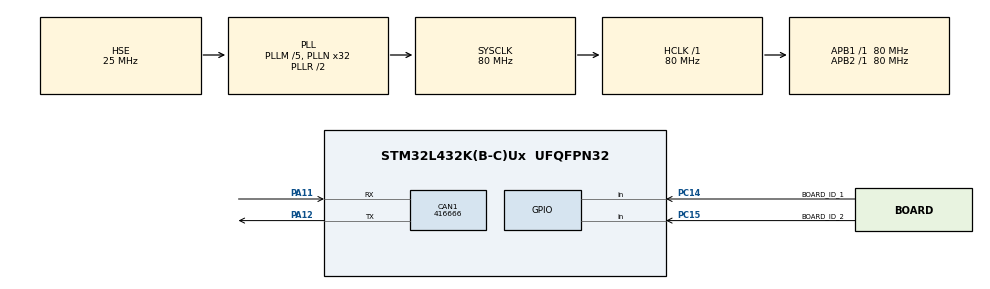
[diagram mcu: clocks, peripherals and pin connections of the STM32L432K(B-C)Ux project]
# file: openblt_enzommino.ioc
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CAN1.BS1=CAN_BS1_10TQ
CAN1.BS2=CAN_BS2_1TQ
CAN1.CalculateBaudRate=416666
CAN1.CalculateTimeBit=2400
CAN1.CalculateTimeQuantum=200.0
Mcu.Family=STM32L4
Mcu.Name=STM32L432K(B-C)Ux
Mcu.Package=UFQFPN32
NVIC.PriorityGroup=NVIC_PRIORITYGROUP_4
PA0.Mode=HSE-External-Clock-Source-for-LittleOrca
PA0.Signal=RCC_CK_IN
PA11.Mode=CAN_Activate
PA11.Signal=CAN1_RX
PA12.Mode=CAN_Activate
PA12.Signal=CAN1_TX
PA13\ (JTMS-SWDIO).Mode=Serial_Wire
PA13\ (JTMS-SWDIO).Signal=SYS_JTMS-SWDIO
PA14\ (JTCK-SWCLK).Mode=Serial_Wire
PA14\ (JTCK-SWCLK).Signal=SYS_JTCK-SWCLK
PC14-OSC32_IN\ (PC14).GPIO_Label=BOARD_ID_1
PC14-OSC32_IN\ (PC14).GPIO_PuPd=GPIO_PULLUP
PC14-OSC32_IN\ (PC14).Signal=GPIO_Input
PC15-OSC32_OUT\ (PC15).GPIO_Label=BOARD_ID_2
PC15-OSC32_OUT\ (PC15).GPIO_PuPd=GPIO_PULLUP
PC15-OSC32_OUT\ (PC15).Signal=GPIO_Input
ProjectManager.HeapSize=0x200
ProjectManager.StackSize=0x400
ProjectManager.TargetToolchain=Makefile
RCC.ADCFreq_Value=20000000
RCC.AHBFreq_Value=80000000
RCC.APB1Freq_Value=80000000
RCC.APB1TimFreq_Value=80000000
RCC.APB2Freq_Value=80000000
RCC.APB2TimFreq_Value=80000000
RCC.CortexFreq_Value=80000000
RCC.HCLKFreq_Value=80000000
RCC.HSE_VALUE=25000000
RCC.HSI48_VALUE=48000000
RCC.HSI_VALUE=16000000
RCC.LSE_VALUE=32768
RCC.MSI_VALUE=4000000
RCC.PLLM=5
RCC.PLLN=32
RCC.PLLSourceVirtual=RCC_PLLSOURCE_HSE
RCC.SYSCLKFreq_VALUE=80000000
RCC.SYSCLKSource=RCC_SYSCLKSOURCE_PLLCLK
RCC.USBFreq_Value=20000000
RCC.VCOOutputFreq_Value=160000000
board=custom

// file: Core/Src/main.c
/* USER CODE BEGIN Header */
/**
 ******************************************************************************
 * @file           : main.c
 * @brief          : Main program body
 ******************************************************************************
 * @attention
 *
 * Copyright (c) 2022 STMicroelectronics.
 * All rights reserved.
 *
 * This software is licensed under terms that can be found in the LICENSE file
 * in the root directory of this software component.
 * If no LICENSE file comes with this software, it is provided AS-IS.
 *
 ******************************************************************************
 */
/* USER CODE END Header */
#include "main.h"

/* USER CODE BEGIN Includes */
#include "boot.h"
/* USER CODE END Includes */

CAN_HandleTypeDef hcan1;

void SystemClock_Config(void);
static void MX_GPIO_Init(void);
static void MX_CAN1_Init(void);

/* USER CODE BEGIN 0 */
board_t get_board_id()
{
    static board_t board = BOARD_NOT_SAMPLED;

    if (board == BOARD_NOT_SAMPLED)
    {
        board = HAL_GPIO_ReadPin(BOARD_ID_1_GPIO_Port, BOARD_ID_1_Pin) | (HAL_GPIO_ReadPin(BOARD_ID_2_GPIO_Port, BOARD_ID_2_Pin) << 1);
    }

    return board;
}

/* USER CODE END 0 */

int main(void)
{

  /* MCU Configuration--------------------------------------------------------*/

  /* Reset of all peripherals, Initializes the Flash interface and the Systick. */
  HAL_Init();

  /* Configure the system clock */
  SystemClock_Config();

  /* Initialize all configured peripherals */
  MX_GPIO_Init();
  MX_CAN1_Init();
  /* USER CODE BEGIN 2 */
    BootInit();
  /* USER CODE END 2 */

  /* Infinite loop */
  /* USER CODE BEGIN WHILE */
    while (1)
    {
        BootTask();
    /* USER CODE END WHILE */

    }
}

void SystemClock_Config(void)
{
  RCC_OscInitTypeDef RCC_OscInitStruct = {0};
  RCC_ClkInitTypeDef RCC_ClkInitStruct = {0};

  /** Configure the main internal regulator output voltage
  */
  if (HAL_PWREx_ControlVoltageScaling(PWR_REGULATOR_VOLTAGE_SCALE1) != HAL_OK)
  {
    Error_Handler();
  }

  /** Initializes the RCC Oscillators according to the specified parameters
  * in the RCC_OscInitTypeDef structure.
  */
  RCC_OscInitStruct.OscillatorType = RCC_OSCILLATORTYPE_HSE;
  RCC_OscInitStruct.HSEState = RCC_HSE_BYPASS;
  RCC_OscInitStruct.PLL.PLLState = RCC_PLL_ON;
  RCC_OscInitStruct.PLL.PLLSource = RCC_PLLSOURCE_HSE;
  RCC_OscInitStruct.PLL.PLLM = 5;
  RCC_OscInitStruct.PLL.PLLN = 32;
  RCC_OscInitStruct.PLL.PLLP = RCC_PLLP_DIV7;
  RCC_OscInitStruct.PLL.PLLQ = RCC_PLLQ_DIV2;
  RCC_OscInitStruct.PLL.PLLR = RCC_PLLR_DIV2;
  if (HAL_RCC_OscConfig(&RCC_OscInitStruct) != HAL_OK)
  {
    Error_Handler();
  }

  /** Initializes the CPU, AHB and APB buses clocks
  */
  RCC_ClkInitStruct.ClockType = RCC_CLOCKTYPE_HCLK|RCC_CLOCKTYPE_SYSCLK
                              |RCC_CLOCKTYPE_PCLK1|RCC_CLOCKTYPE_PCLK2;
  RCC_ClkInitStruct.SYSCLKSource = RCC_SYSCLKSOURCE_PLLCLK;
  RCC_ClkInitStruct.AHBCLKDivider = RCC_SYSCLK_DIV1;
  RCC_ClkInitStruct.APB1CLKDivider = RCC_HCLK_DIV1;
  RCC_ClkInitStruct.APB2CLKDivider = RCC_HCLK_DIV1;

  if (HAL_RCC_ClockConfig(&RCC_ClkInitStruct, FLASH_LATENCY_4) != HAL_OK)
  {
    Error_Handler();
  }
}

static void MX_CAN1_Init(void)
{

  hcan1.Instance = CAN1;
  hcan1.Init.Prescaler = 16;
  hcan1.Init.Mode = CAN_MODE_NORMAL;
  hcan1.Init.SyncJumpWidth = CAN_SJW_1TQ;
  hcan1.Init.TimeSeg1 = CAN_BS1_10TQ;
  hcan1.Init.TimeSeg2 = CAN_BS2_1TQ;
  hcan1.Init.TimeTriggeredMode = DISABLE;
  hcan1.Init.AutoBusOff = DISABLE;
  hcan1.Init.AutoWakeUp = DISABLE;
  hcan1.Init.AutoRetransmission = DISABLE;
  hcan1.Init.ReceiveFifoLocked = DISABLE;
  hcan1.Init.TransmitFifoPriority = DISABLE;
  if (HAL_CAN_Init(&hcan1) != HAL_OK)
  {
    Error_Handler();
  }

}

static void MX_GPIO_Init(void)
{
  GPIO_InitTypeDef GPIO_InitStruct = {0};

  /* GPIO Ports Clock Enable */
  __HAL_RCC_GPIOC_CLK_ENABLE();
  __HAL_RCC_GPIOA_CLK_ENABLE();
  __HAL_RCC_GPIOB_CLK_ENABLE();
  __HAL_RCC_GPIOH_CLK_ENABLE();

  /*Configure GPIO pins : BOARD_ID_1_Pin BOARD_ID_2_Pin */
  GPIO_InitStruct.Pin = BOARD_ID_1_Pin|BOARD_ID_2_Pin;
  GPIO_InitStruct.Mode = GPIO_MODE_INPUT;
  GPIO_InitStruct.Pull = GPIO_PULLUP;
  HAL_GPIO_Init(GPIOC, &GPIO_InitStruct);

  /*Configure GPIO pins : PA1 PA2 PA3 PA4
                           PA5 PA6 PA7 PA8
                           PA9 PA10 PA15 */
  GPIO_InitStruct.Pin = GPIO_PIN_1|GPIO_PIN_2|GPIO_PIN_3|GPIO_PIN_4
                          |GPIO_PIN_5|GPIO_PIN_6|GPIO_PIN_7|GPIO_PIN_8
                          |GPIO_PIN_9|GPIO_PIN_10|GPIO_PIN_15;
  GPIO_InitStruct.Mode = GPIO_MODE_ANALOG;
  GPIO_InitStruct.Pull = GPIO_NOPULL;
  HAL_GPIO_Init(GPIOA, &GPIO_InitStruct);

  /*Configure GPIO pins : PB0 PB1 PB3 PB4
                           PB5 PB6 PB7 */
  GPIO_InitStruct.Pin = GPIO_PIN_0|GPIO_PIN_1|GPIO_PIN_3|GPIO_PIN_4
                          |GPIO_PIN_5|GPIO_PIN_6|GPIO_PIN_7;
  GPIO_InitStruct.Mode = GPIO_MODE_ANALOG;
  GPIO_InitStruct.Pull = GPIO_NOPULL;
  HAL_GPIO_Init(GPIOB, &GPIO_InitStruct);

  /*Configure GPIO pin : PH3 */
  GPIO_InitStruct.Pin = GPIO_PIN_3;
  GPIO_InitStruct.Mode = GPIO_MODE_ANALOG;
  GPIO_InitStruct.Pull = GPIO_NOPULL;
  HAL_GPIO_Init(GPIOH, &GPIO_InitStruct);

}

void Error_Handler(void)
{
    __disable_irq();
    while (1)
    {
    }
}
